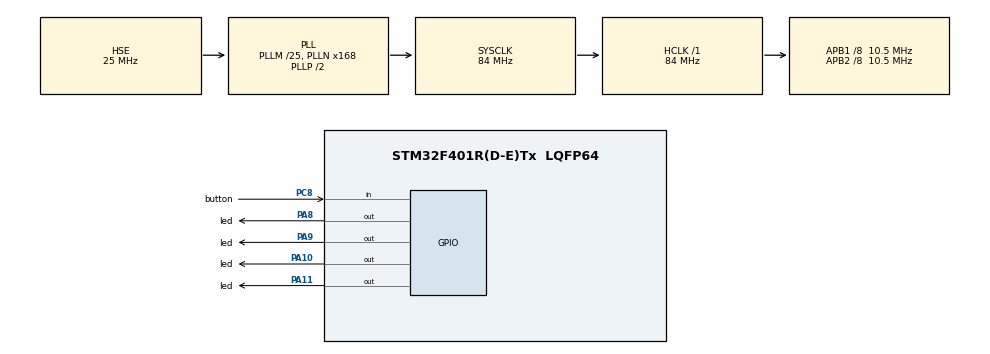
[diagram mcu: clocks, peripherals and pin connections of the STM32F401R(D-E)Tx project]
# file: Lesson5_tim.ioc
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Mcu.Family=STM32F4
Mcu.Name=STM32F401R(D-E)Tx
Mcu.Package=LQFP64
NVIC.PriorityGroup=NVIC_PRIORITYGROUP_4
NVIC.TIM1_UP_TIM10_IRQn=true\:0\:0\:false\:false\:true\:true\:true\:true
PA10.GPIO_Label=led
PA10.Signal=GPIO_Output
PA11.GPIO_Label=led
PA11.Signal=GPIO_Output
PA13.Mode=Serial_Wire
PA13.Signal=SYS_JTMS-SWDIO
PA14.Mode=Serial_Wire
PA14.Signal=SYS_JTCK-SWCLK
PA8.GPIO_Label=led
PA8.Signal=GPIO_Output
PA9.GPIO_Label=led
PA9.Signal=GPIO_Output
PC8.GPIO_Label=button
PC8.Signal=GPIO_Input
PH0\ -\ OSC_IN.Mode=HSE-External-Oscillator
PH0\ -\ OSC_IN.Signal=RCC_OSC_IN
PH1\ -\ OSC_OUT.Mode=HSE-External-Oscillator
PH1\ -\ OSC_OUT.Signal=RCC_OSC_OUT
ProjectManager.HeapSize=0x200
ProjectManager.StackSize=0x400
ProjectManager.TargetToolchain=STM32CubeIDE
RCC.48MHZClocksFreq_Value=42000000
RCC.AHBFreq_Value=84000000
RCC.APB1CLKDivider=RCC_HCLK_DIV8
RCC.APB1Freq_Value=10500000
RCC.APB1TimFreq_Value=21000000
RCC.APB2CLKDivider=RCC_HCLK_DIV8
RCC.APB2Freq_Value=10500000
RCC.APB2TimFreq_Value=21000000
RCC.CortexFreq_Value=84000000
RCC.HCLKFreq_Value=84000000
RCC.HSE_VALUE=25000000
RCC.HSI_VALUE=16000000
RCC.LSE_VALUE=32768
RCC.PLLM=25
RCC.PLLN=168
RCC.PLLSourceVirtual=RCC_PLLSOURCE_HSE
RCC.SYSCLKFreq_VALUE=84000000
RCC.SYSCLKSource=RCC_SYSCLKSOURCE_PLLCLK
RCC.VCOOutputFreq_Value=168000000
TIM10.Period=499
TIM10.Prescaler=20999
VP_TIM10_VS_ClockSourceINT.Mode=Enable_Timer
board=custom

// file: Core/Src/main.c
/* USER CODE BEGIN Header */
/**
  ******************************************************************************
  * @file           : main.c
  * @brief          : Main program body
  ******************************************************************************
  * @attention
  *
  * Copyright (c) 2024 STMicroelectronics.
  * All rights reserved.
  *
  * This software is licensed under terms that can be found in the LICENSE file
  * in the root directory of this software component.
  * If no LICENSE file comes with this software, it is provided AS-IS.
  *
  ******************************************************************************
  */
/* USER CODE END Header */
#include "main.h"

TIM_HandleTypeDef htim10;

void SystemClock_Config(void);
static void MX_GPIO_Init(void);
static void MX_TIM10_Init(void);

/* USER CODE BEGIN 0 */
uint8_t tim10_counter;
/* USER CODE END 0 */

int main(void)
{

  /* MCU Configuration--------------------------------------------------------*/

  /* Reset of all peripherals, Initializes the Flash interface and the Systick. */
  HAL_Init();

  /* Configure the system clock */
  SystemClock_Config();

  /* Initialize all configured peripherals */
  MX_GPIO_Init();
  MX_TIM10_Init();

  /* Infinite loop */
  /* USER CODE BEGIN WHILE */
  while (1)
  {
	  if (HAL_GPIO_ReadPin(GPIOC, GPIO_PIN_8) == GPIO_PIN_SET){
		  HAL_TIM_Base_Start_IT(&htim10);
	  }
	  else {
		  HAL_TIM_Base_Stop_IT(&htim10);
		  HAL_GPIO_WritePin(GPIOA, GPIO_PIN_8|GPIO_PIN_9|GPIO_PIN_10|GPIO_PIN_11, GPIO_PIN_RESET);
	  }
    /* USER CODE END WHILE */

  }
}

void SystemClock_Config(void)
{
  RCC_OscInitTypeDef RCC_OscInitStruct = {0};
  RCC_ClkInitTypeDef RCC_ClkInitStruct = {0};

  /** Configure the main internal regulator output voltage
  */
  __HAL_RCC_PWR_CLK_ENABLE();
  __HAL_PWR_VOLTAGESCALING_CONFIG(PWR_REGULATOR_VOLTAGE_SCALE2);

  /** Initializes the RCC Oscillators according to the specified parameters
  * in the RCC_OscInitTypeDef structure.
  */
  RCC_OscInitStruct.OscillatorType = RCC_OSCILLATORTYPE_HSE;
  RCC_OscInitStruct.HSEState = RCC_HSE_ON;
  RCC_OscInitStruct.PLL.PLLState = RCC_PLL_ON;
  RCC_OscInitStruct.PLL.PLLSource = RCC_PLLSOURCE_HSE;
  RCC_OscInitStruct.PLL.PLLM = 25;
  RCC_OscInitStruct.PLL.PLLN = 168;
  RCC_OscInitStruct.PLL.PLLP = RCC_PLLP_DIV2;
  RCC_OscInitStruct.PLL.PLLQ = 4;
  if (HAL_RCC_OscConfig(&RCC_OscInitStruct) != HAL_OK)
  {
    Error_Handler();
  }

  /** Initializes the CPU, AHB and APB buses clocks
  */
  RCC_ClkInitStruct.ClockType = RCC_CLOCKTYPE_HCLK|RCC_CLOCKTYPE_SYSCLK
                              |RCC_CLOCKTYPE_PCLK1|RCC_CLOCKTYPE_PCLK2;
  RCC_ClkInitStruct.SYSCLKSource = RCC_SYSCLKSOURCE_PLLCLK;
  RCC_ClkInitStruct.AHBCLKDivider = RCC_SYSCLK_DIV1;
  RCC_ClkInitStruct.APB1CLKDivider = RCC_HCLK_DIV8;
  RCC_ClkInitStruct.APB2CLKDivider = RCC_HCLK_DIV8;

  if (HAL_RCC_ClockConfig(&RCC_ClkInitStruct, FLASH_LATENCY_2) != HAL_OK)
  {
    Error_Handler();
  }
}

static void MX_TIM10_Init(void)
{

  htim10.Instance = TIM10;
  htim10.Init.Prescaler = 20999;
  htim10.Init.CounterMode = TIM_COUNTERMODE_UP;
  htim10.Init.Period = 499;
  htim10.Init.ClockDivision = TIM_CLOCKDIVISION_DIV1;
  htim10.Init.AutoReloadPreload = TIM_AUTORELOAD_PRELOAD_DISABLE;
  if (HAL_TIM_Base_Init(&htim10) != HAL_OK)
  {
    Error_Handler();
  }

}

static void MX_GPIO_Init(void)
{
  GPIO_InitTypeDef GPIO_InitStruct = {0};

  /* GPIO Ports Clock Enable */
  __HAL_RCC_GPIOH_CLK_ENABLE();
  __HAL_RCC_GPIOC_CLK_ENABLE();
  __HAL_RCC_GPIOA_CLK_ENABLE();

  /*Configure GPIO pin Output Level */
  HAL_GPIO_WritePin(GPIOA, led_Pin|ledA9_Pin|ledA10_Pin|ledA11_Pin, GPIO_PIN_RESET);

  /*Configure GPIO pin : button_Pin */
  GPIO_InitStruct.Pin = button_Pin;
  GPIO_InitStruct.Mode = GPIO_MODE_INPUT;
  GPIO_InitStruct.Pull = GPIO_NOPULL;
  HAL_GPIO_Init(button_GPIO_Port, &GPIO_InitStruct);

  /*Configure GPIO pins : led_Pin ledA9_Pin ledA10_Pin ledA11_Pin */
  GPIO_InitStruct.Pin = led_Pin|ledA9_Pin|ledA10_Pin|ledA11_Pin;
  GPIO_InitStruct.Mode = GPIO_MODE_OUTPUT_PP;
  GPIO_InitStruct.Pull = GPIO_NOPULL;
  GPIO_InitStruct.Speed = GPIO_SPEED_FREQ_LOW;
  HAL_GPIO_Init(GPIOA, &GPIO_InitStruct);

}

void Error_Handler(void)
{
  __disable_irq();
  while (1)
  {
  }
}
